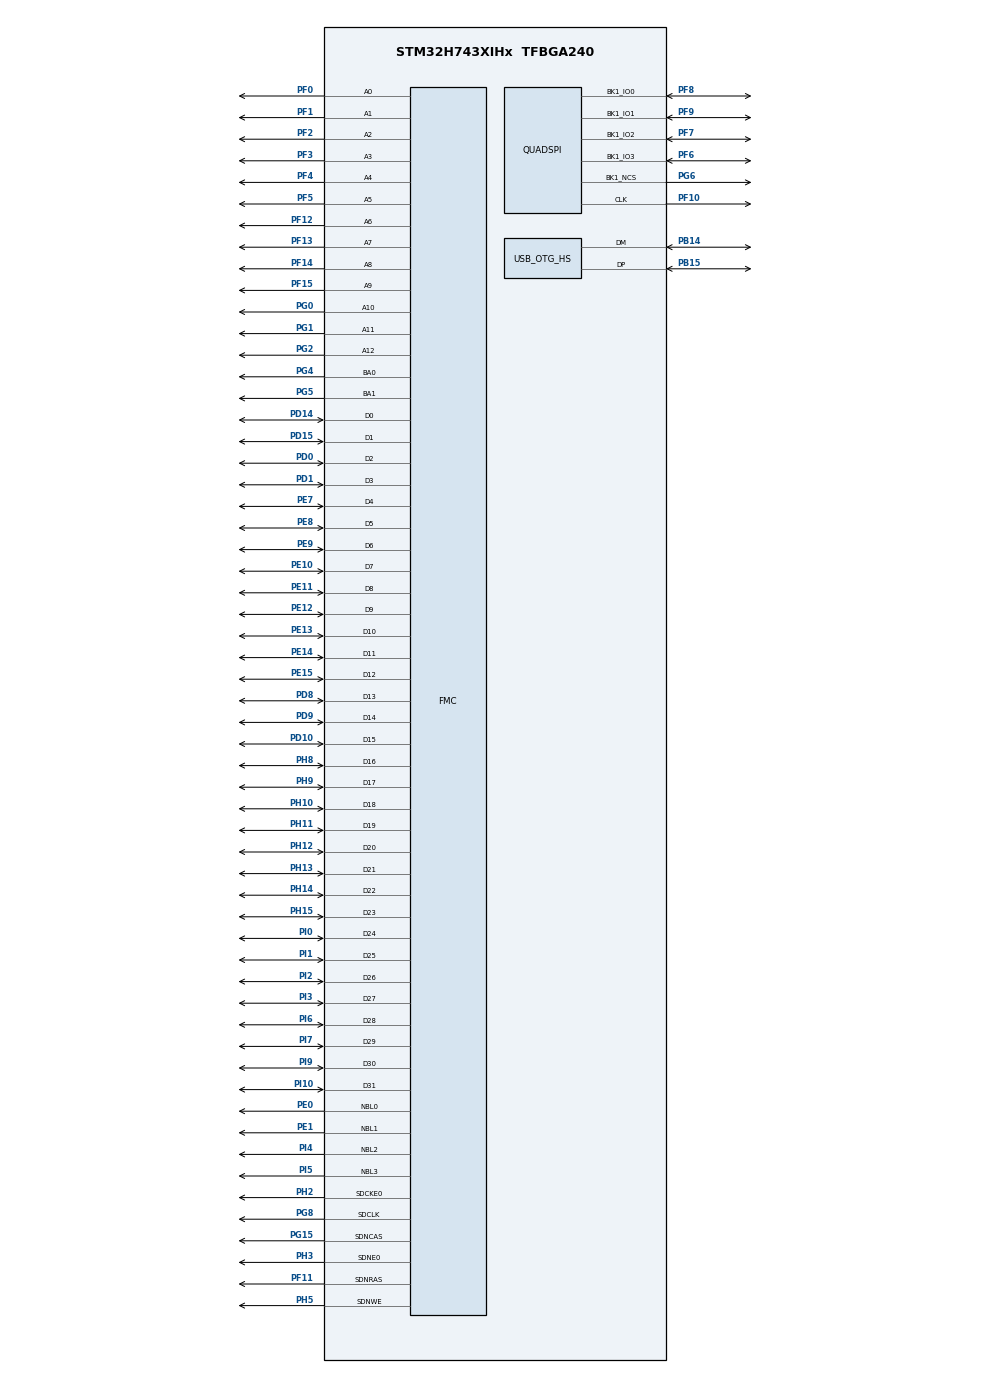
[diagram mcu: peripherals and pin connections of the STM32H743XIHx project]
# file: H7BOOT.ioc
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CORTEX_M7.AccessPermission_S-Cortex_Memory_Protection_Unit_Region1_Settings_S=MPU_REGION_FULL_ACCESS
CORTEX_M7.AccessPermission_S-Cortex_Memory_Protection_Unit_Region2_Settings_S=MPU_REGION_FULL_ACCESS
CORTEX_M7.AccessPermission_Spec=MPU_REGION_FULL_ACCESS
CORTEX_M7.BaseAddress_S-Cortex_Memory_Protection_Unit_Region1_Settings_S=0x90000000
CORTEX_M7.BaseAddress_S-Cortex_Memory_Protection_Unit_Region2_Settings_S=0xC0000000
CORTEX_M7.BaseAddress_Spec=0x24000000
CORTEX_M7.CPU_DCache=Enabled
CORTEX_M7.CPU_ICache=Enabled
CORTEX_M7.DisableExec_S-Cortex_Memory_Protection_Unit_Region2_Settings_S=MPU_INSTRUCTION_ACCESS_DISABLE
CORTEX_M7.Enable_S-Cortex_Memory_Protection_Unit_Region1_Settings_S=MPU_REGION_ENABLE
CORTEX_M7.Enable_S-Cortex_Memory_Protection_Unit_Region2_Settings_S=MPU_REGION_ENABLE
CORTEX_M7.Enable_Spec=MPU_REGION_ENABLE
CORTEX_M7.IsBufferable_S-Cortex_Memory_Protection_Unit_Region1_Settings_S=MPU_ACCESS_BUFFERABLE
CORTEX_M7.IsBufferable_S-Cortex_Memory_Protection_Unit_Region2_Settings_S=MPU_ACCESS_BUFFERABLE
CORTEX_M7.IsBufferable_Spec=MPU_ACCESS_BUFFERABLE
CORTEX_M7.IsCacheable_S-Cortex_Memory_Protection_Unit_Region1_Settings_S=MPU_ACCESS_CACHEABLE
CORTEX_M7.IsCacheable_S-Cortex_Memory_Protection_Unit_Region2_Settings_S=MPU_ACCESS_CACHEABLE
CORTEX_M7.IsCacheable_Spec=MPU_ACCESS_CACHEABLE
CORTEX_M7.IsShareable_S-Cortex_Memory_Protection_Unit_Region2_Settings_S=MPU_ACCESS_SHAREABLE
CORTEX_M7.MPU_Control=MPU_HFNMI_PRIVDEF
CORTEX_M7.Size_S-Cortex_Memory_Protection_Unit_Region1_Settings_S=MPU_REGION_SIZE_32MB
CORTEX_M7.Size_S-Cortex_Memory_Protection_Unit_Region2_Settings_S=MPU_REGION_SIZE_32MB
CORTEX_M7.Size_Spec=MPU_REGION_SIZE_128KB
CORTEX_M7.default_mode_Activation=1
FMC.CASLatency1=FMC_SDRAM_CAS_LATENCY_3
FMC.ColumnBitsNumber1=FMC_SDRAM_COLUMN_BITS_NUM_9
FMC.ExitSelfRefreshDelay1=14
FMC.LoadToActiveDelay1=2
FMC.RCDDelay1=4
FMC.RPDelay1=4
FMC.ReadBurst1=FMC_SDRAM_RBURST_ENABLE
FMC.ReadPipeDelay1=FMC_SDRAM_RPIPE_DELAY_1
FMC.RowCycleDelay1=13
FMC.SDClockPeriod1=FMC_SDRAM_CLOCK_PERIOD_2
FMC.SelfRefreshTime1=9
FMC.WriteRecoveryTime1=5
Mcu.Family=STM32H7
Mcu.Name=STM32H743XIHx
Mcu.Package=TFBGA240
NVIC.OTG_HS_IRQn=true\:0\:0\:false\:false\:true\:false\:true\:true
NVIC.PriorityGroup=NVIC_PRIORITYGROUP_4
PA13\ (JTMS/SWDIO).Mode=Serial_Wire
PA13\ (JTMS/SWDIO).Signal=DEBUG_JTMS-SWDIO
PA14\ (JTCK/SWCLK).Mode=Serial_Wire
PA14\ (JTCK/SWCLK).Signal=DEBUG_JTCK-SWCLK
PB14.GPIO_Speed=GPIO_SPEED_FREQ_VERY_HIGH
PB14.Mode=Host_FS
PB14.Signal=USB_OTG_HS_DM
PB15.GPIO_Speed=GPIO_SPEED_FREQ_VERY_HIGH
PB15.Mode=Host_FS
PB15.Signal=USB_OTG_HS_DP
PC14-OSC32_IN\ (OSC32_IN).Mode=LSE-External-Oscillator
PC14-OSC32_IN\ (OSC32_IN).Signal=RCC_OSC32_IN
PC15-OSC32_OUT\ (OSC32_OUT).Mode=LSE-External-Oscillator
PC15-OSC32_OUT\ (OSC32_OUT).Signal=RCC_OSC32_OUT
PD0.Signal=FMC_D2_DA2
PD1.Signal=FMC_D3_DA3
PD10.Signal=FMC_D15_DA15
PD14.Signal=FMC_D0_DA0
PD15.Signal=FMC_D1_DA1
PD8.Signal=FMC_D13_DA13
PD9.Signal=FMC_D14_DA14
PE0.Signal=FMC_NBL0
PE1.Signal=FMC_NBL1
PE10.Signal=FMC_D7_DA7
PE11.Signal=FMC_D8_DA8
PE12.Signal=FMC_D9_DA9
PE13.Signal=FMC_D10_DA10
PE14.Signal=FMC_D11_DA11
PE15.Signal=FMC_D12_DA12
PE7.Signal=FMC_D4_DA4
PE8.Signal=FMC_D5_DA5
PE9.Signal=FMC_D6_DA6
PF0.Signal=FMC_A0
PF1.Signal=FMC_A1
PF10.GPIO_Speed=GPIO_SPEED_FREQ_VERY_HIGH
PF10.Mode=Single Bank 1
PF10.Signal=QUADSPI_CLK
PF11.Signal=FMC_SDNRAS
PF12.Signal=FMC_A6
PF13.Signal=FMC_A7
PF14.Signal=FMC_A8
PF15.Signal=FMC_A9
PF2.Signal=FMC_A2
PF3.Signal=FMC_A3
PF4.Signal=FMC_A4
PF5.Signal=FMC_A5
PF6.GPIO_Speed=GPIO_SPEED_FREQ_VERY_HIGH
PF6.Mode=Single Bank 1
PF6.Signal=QUADSPI_BK1_IO3
PF7.GPIO_Speed=GPIO_SPEED_FREQ_VERY_HIGH
PF7.Mode=Single Bank 1
PF7.Signal=QUADSPI_BK1_IO2
PF8.GPIO_Speed=GPIO_SPEED_FREQ_VERY_HIGH
PF8.Mode=Single Bank 1
PF8.Signal=QUADSPI_BK1_IO0
PF9.GPIO_Speed=GPIO_SPEED_FREQ_VERY_HIGH
PF9.Mode=Single Bank 1
PF9.Signal=QUADSPI_BK1_IO1
PG0.Signal=FMC_A10
PG1.Signal=FMC_A11
PG15.Signal=FMC_SDNCAS
PG2.Signal=FMC_A12
PG4.Signal=FMC_A14_BA0
PG5.Signal=FMC_A15_BA1
PG6.GPIO_Speed=GPIO_SPEED_FREQ_VERY_HIGH
PG6.Mode=Single Bank 1
PG6.Signal=QUADSPI_BK1_NCS
PG8.Signal=FMC_SDCLK
PH0-OSC_IN\ (PH0).Mode=HSE-External-Oscillator
PH0-OSC_IN\ (PH0).Signal=RCC_OSC_IN
PH1-OSC_OUT\ (PH1).Mode=HSE-External-Oscillator
PH1-OSC_OUT\ (PH1).Signal=RCC_OSC_OUT
PH10.Signal=FMC_D18
PH11.Signal=FMC_D19
PH12.Signal=FMC_D20
PH13.Signal=FMC_D21
PH14.Signal=FMC_D22
PH15.Signal=FMC_D23
PH2.Mode=SdramChipSelect1_1
PH2.Signal=FMC_SDCKE0
PH3.Mode=SdramChipSelect1_1
PH3.Signal=FMC_SDNE0
PH5.Signal=FMC_SDNWE
PH8.Signal=FMC_D16
PH9.Signal=FMC_D17
PI0.Signal=FMC_D24
PI1.Signal=FMC_D25
PI10.Signal=FMC_D31
PI2.Signal=FMC_D26
PI3.Signal=FMC_D27
PI4.Signal=FMC_NBL2
PI5.Signal=FMC_NBL3
PI6.Signal=FMC_D28
PI7.Signal=FMC_D29
PI9.Signal=FMC_D30
ProjectManager.HeapSize=0x1000
ProjectManager.StackSize=0x2000
ProjectManager.TargetToolchain=CMake
QUADSPI.ChipSelectHighTime=QSPI_CS_HIGH_TIME_2_CYCLE
QUADSPI.ClockPrescaler=1
QUADSPI.FifoThreshold=4
QUADSPI.FlashSize=25
QUADSPI.SampleShifting=QSPI_SAMPLE_SHIFTING_HALFCYCLE
RCC.ADCFreq_Value=140000000
RCC.APB1Freq_Value=100000000
RCC.APB2Freq_Value=100000000
RCC.APB3Freq_Value=100000000
RCC.APB4Freq_Value=100000000
RCC.CortexFreq_Value=400000000
RCC.D1PPRE=RCC_APB3_DIV2
RCC.D2PPRE1=RCC_APB1_DIV2
RCC.D2PPRE2=RCC_APB2_DIV2
RCC.D3PPRE=RCC_APB4_DIV2
RCC.DIVM1=5
RCC.DIVM2=25
RCC.DIVM3=25
RCC.DIVN1=160
RCC.DIVN2=280
RCC.DIVN3=240
RCC.DIVQ1=16
RCC.HCLKFreq_Value=200000000
RCC.HPRE=RCC_HCLK_DIV2
RCC.PLL2FRACN=0
RCC.PLL3FRACN=0
RCC.PLLFRACN=0
RCC.PLLSourceVirtual=RCC_PLLSOURCE_HSE
RCC.SYSCLKFreq_VALUE=400000000
RCC.SYSCLKSource=RCC_SYSCLKSOURCE_PLLCLK
RCC.USBFreq_Value=50000000
SH.FMC_A0.0=FMC_A0,13b-sda1
SH.FMC_A1.0=FMC_A1,13b-sda1
SH.FMC_A10.0=FMC_A10,13b-sda1
SH.FMC_A11.0=FMC_A11,13b-sda1
SH.FMC_A12.0=FMC_A12,13b-sda1
SH.FMC_A14_BA0.0=FMC_BA0,FourSdramBanks1
SH.FMC_A15_BA1.0=FMC_BA1,FourSdramBanks1
SH.FMC_A2.0=FMC_A2,13b-sda1
SH.FMC_A3.0=FMC_A3,13b-sda1
SH.FMC_A4.0=FMC_A4,13b-sda1
SH.FMC_A5.0=FMC_A5,13b-sda1
SH.FMC_A6.0=FMC_A6,13b-sda1
SH.FMC_A7.0=FMC_A7,13b-sda1
SH.FMC_A8.0=FMC_A8,13b-sda1
SH.FMC_A9.0=FMC_A9,13b-sda1
SH.FMC_D0_DA0.0=FMC_D0,sd-32b-d1
SH.FMC_D10_DA10.0=FMC_D10,sd-32b-d1
SH.FMC_D11_DA11.0=FMC_D11,sd-32b-d1
SH.FMC_D12_DA12.0=FMC_D12,sd-32b-d1
SH.FMC_D13_DA13.0=FMC_D13,sd-32b-d1
SH.FMC_D14_DA14.0=FMC_D14,sd-32b-d1
SH.FMC_D15_DA15.0=FMC_D15,sd-32b-d1
SH.FMC_D16.0=FMC_D16,sd-32b-d1
SH.FMC_D17.0=FMC_D17,sd-32b-d1
SH.FMC_D18.0=FMC_D18,sd-32b-d1
SH.FMC_D19.0=FMC_D19,sd-32b-d1
SH.FMC_D1_DA1.0=FMC_D1,sd-32b-d1
SH.FMC_D20.0=FMC_D20,sd-32b-d1
SH.FMC_D21.0=FMC_D21,sd-32b-d1
SH.FMC_D22.0=FMC_D22,sd-32b-d1
SH.FMC_D23.0=FMC_D23,sd-32b-d1
SH.FMC_D24.0=FMC_D24,sd-32b-d1
SH.FMC_D25.0=FMC_D25,sd-32b-d1
SH.FMC_D26.0=FMC_D26,sd-32b-d1
SH.FMC_D27.0=FMC_D27,sd-32b-d1
SH.FMC_D28.0=FMC_D28,sd-32b-d1
SH.FMC_D29.0=FMC_D29,sd-32b-d1
SH.FMC_D2_DA2.0=FMC_D2,sd-32b-d1
SH.FMC_D30.0=FMC_D30,sd-32b-d1
SH.FMC_D31.0=FMC_D31,sd-32b-d1
SH.FMC_D3_DA3.0=FMC_D3,sd-32b-d1
SH.FMC_D4_DA4.0=FMC_D4,sd-32b-d1
SH.FMC_D5_DA5.0=FMC_D5,sd-32b-d1
SH.FMC_D6_DA6.0=FMC_D6,sd-32b-d1
SH.FMC_D7_DA7.0=FMC_D7,sd-32b-d1
SH.FMC_D8_DA8.0=FMC_D8,sd-32b-d1
SH.FMC_D9_DA9.0=FMC_D9,sd-32b-d1
SH.FMC_NBL0.0=FMC_NBL0,Sd4ByteEnable1
SH.FMC_NBL1.0=FMC_NBL1,Sd4ByteEnable1
SH.FMC_NBL2.0=FMC_NBL2,Sd4ByteEnable1
SH.FMC_NBL3.0=FMC_NBL3,Sd4ByteEnable1
SH.FMC_SDCLK.0=FMC_SDCLK,13b-sda1
SH.FMC_SDNCAS.0=FMC_SDNCAS,13b-sda1
SH.FMC_SDNRAS.0=FMC_SDNRAS,13b-sda1
SH.FMC_SDNWE.0=FMC_SDNWE,13b-sda1
USB_HOST.SW_VBUS_DRIVE_MSC_HS=true
USB_HOST.USBH_HandleTypeDef-MSC_HS=hUsbHostHS
USB_HOST.VirtualModeHS=Msc
USB_OTG_HS.VirtualMode-Host_FS=Host_FS
VP_CRC_VS_CRC.Mode=CRC_Activate
VP_FATFS_VS_USB.Mode=USB
VP_IWDG1_VS_IWDG.Mode=IWDG_Activate
VP_MEMORYMAP_VS_MEMORYMAP.Mode=CurAppReg
VP_USB_HOST_VS_USB_HOST_MSC_HS.Mode=MSC_HS
board=custom

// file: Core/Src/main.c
/* USER CODE BEGIN Header */
/**
  ******************************************************************************
  * @file           : main.c
  * @brief          : Main program body
  ******************************************************************************
  * @attention
  *
  * Copyright (c) 2025 STMicroelectronics.
  * All rights reserved.
  *
  * This software is licensed under terms that can be found in the LICENSE file
  * in the root directory of this software component.
  * If no LICENSE file comes with this software, it is provided AS-IS.
  *
  ******************************************************************************
  */
/* USER CODE END Header */
#include "main.h"
#include "fatfs.h"
#include "usb_host.h"

/* USER CODE BEGIN Includes */
#include "app.h"
// #include "bsp.h"
/* USER CODE END Includes */

CRC_HandleTypeDef hcrc;

IWDG_HandleTypeDef hiwdg1;

QSPI_HandleTypeDef hqspi;

SDRAM_HandleTypeDef hsdram1;

void SystemClock_Config(void);
static void MPU_Config(void);
static void MX_GPIO_Init(void);
static void MX_FMC_Init(void);
static void MX_QUADSPI_Init(void);
static void MX_IWDG1_Init(void);
static void MX_CRC_Init(void);
void MX_USB_HOST_Process(void);

int main(void)
{

  /* MPU Configuration--------------------------------------------------------*/
  MPU_Config();

  /* Enable the CPU Cache */

  /* Enable I-Cache---------------------------------------------------------*/
  SCB_EnableICache();

  /* Enable D-Cache---------------------------------------------------------*/
  SCB_EnableDCache();

  /* MCU Configuration--------------------------------------------------------*/

  /* Reset of all peripherals, Initializes the Flash interface and the Systick. */
  HAL_Init();

  /* Configure the system clock */
  SystemClock_Config();

  /* Initialize all configured peripherals */
  MX_GPIO_Init();
  MX_FMC_Init();
  MX_QUADSPI_Init();
  MX_FATFS_Init();
  MX_USB_HOST_Init();
  MX_IWDG1_Init();
  MX_CRC_Init();

  /* Infinite loop */
  /* USER CODE BEGIN WHILE */
  while (1)
  {
    HAL_IWDG_Refresh(&hiwdg1);
    /* USER CODE END WHILE */
    MX_USB_HOST_Process();

  }
}

void SystemClock_Config(void)
{
  RCC_OscInitTypeDef RCC_OscInitStruct = {0};
  RCC_ClkInitTypeDef RCC_ClkInitStruct = {0};

  /** Supply configuration update enable
  */
  HAL_PWREx_ConfigSupply(PWR_LDO_SUPPLY);

  /** Configure the main internal regulator output voltage
  */
  __HAL_PWR_VOLTAGESCALING_CONFIG(PWR_REGULATOR_VOLTAGE_SCALE1);

  while(!__HAL_PWR_GET_FLAG(PWR_FLAG_VOSRDY)) {}

  /** Initializes the RCC Oscillators according to the specified parameters
  * in the RCC_OscInitTypeDef structure.
  */
  RCC_OscInitStruct.OscillatorType = RCC_OSCILLATORTYPE_LSI|RCC_OSCILLATORTYPE_HSE;
  RCC_OscInitStruct.HSEState = RCC_HSE_ON;
  RCC_OscInitStruct.LSIState = RCC_LSI_ON;
  RCC_OscInitStruct.PLL.PLLState = RCC_PLL_ON;
  RCC_OscInitStruct.PLL.PLLSource = RCC_PLLSOURCE_HSE;
  RCC_OscInitStruct.PLL.PLLM = 5;
  RCC_OscInitStruct.PLL.PLLN = 160;
  RCC_OscInitStruct.PLL.PLLP = 2;
  RCC_OscInitStruct.PLL.PLLQ = 16;
  RCC_OscInitStruct.PLL.PLLR = 2;
  RCC_OscInitStruct.PLL.PLLRGE = RCC_PLL1VCIRANGE_2;
  RCC_OscInitStruct.PLL.PLLVCOSEL = RCC_PLL1VCOWIDE;
  RCC_OscInitStruct.PLL.PLLFRACN = 0;
  if (HAL_RCC_OscConfig(&RCC_OscInitStruct) != HAL_OK)
  {
    Error_Handler();
  }

  /** Initializes the CPU, AHB and APB buses clocks
  */
  RCC_ClkInitStruct.ClockType = RCC_CLOCKTYPE_HCLK|RCC_CLOCKTYPE_SYSCLK
                              |RCC_CLOCKTYPE_PCLK1|RCC_CLOCKTYPE_PCLK2
                              |RCC_CLOCKTYPE_D3PCLK1|RCC_CLOCKTYPE_D1PCLK1;
  RCC_ClkInitStruct.SYSCLKSource = RCC_SYSCLKSOURCE_PLLCLK;
  RCC_ClkInitStruct.SYSCLKDivider = RCC_SYSCLK_DIV1;
  RCC_ClkInitStruct.AHBCLKDivider = RCC_HCLK_DIV2;
  RCC_ClkInitStruct.APB3CLKDivider = RCC_APB3_DIV2;
  RCC_ClkInitStruct.APB1CLKDivider = RCC_APB1_DIV2;
  RCC_ClkInitStruct.APB2CLKDivider = RCC_APB2_DIV2;
  RCC_ClkInitStruct.APB4CLKDivider = RCC_APB4_DIV2;

  if (HAL_RCC_ClockConfig(&RCC_ClkInitStruct, FLASH_LATENCY_2) != HAL_OK)
  {
    Error_Handler();
  }
}

static void MX_CRC_Init(void)
{

  hcrc.Instance = CRC;
  hcrc.Init.DefaultPolynomialUse = DEFAULT_POLYNOMIAL_ENABLE;
  hcrc.Init.DefaultInitValueUse = DEFAULT_INIT_VALUE_ENABLE;
  hcrc.Init.InputDataInversionMode = CRC_INPUTDATA_INVERSION_NONE;
  hcrc.Init.OutputDataInversionMode = CRC_OUTPUTDATA_INVERSION_DISABLE;
  hcrc.InputDataFormat = CRC_INPUTDATA_FORMAT_BYTES;
  if (HAL_CRC_Init(&hcrc) != HAL_OK)
  {
    Error_Handler();
  }

}

static void MX_IWDG1_Init(void)
{

  hiwdg1.Instance = IWDG1;
  hiwdg1.Init.Prescaler = IWDG_PRESCALER_4;
  hiwdg1.Init.Window = 4095;
  hiwdg1.Init.Reload = 4095;
  if (HAL_IWDG_Init(&hiwdg1) != HAL_OK)
  {
    Error_Handler();
  }

}

static void MX_QUADSPI_Init(void)
{

  /* QUADSPI parameter configuration*/
  hqspi.Instance = QUADSPI;
  hqspi.Init.ClockPrescaler = 1;
  hqspi.Init.FifoThreshold = 4;
  hqspi.Init.SampleShifting = QSPI_SAMPLE_SHIFTING_HALFCYCLE;
  hqspi.Init.FlashSize = 25;
  hqspi.Init.ChipSelectHighTime = QSPI_CS_HIGH_TIME_2_CYCLE;
  hqspi.Init.ClockMode = QSPI_CLOCK_MODE_0;
  hqspi.Init.FlashID = QSPI_FLASH_ID_1;
  hqspi.Init.DualFlash = QSPI_DUALFLASH_DISABLE;
  if (HAL_QSPI_Init(&hqspi) != HAL_OK)
  {
    Error_Handler();
  }

}

/* FMC initialization function */
static void MX_FMC_Init(void)
{

  FMC_SDRAM_TimingTypeDef SdramTiming = {0};

  /** Perform the SDRAM1 memory initialization sequence
  */
  hsdram1.Instance = FMC_SDRAM_DEVICE;
  /* hsdram1.Init */
  hsdram1.Init.SDBank = FMC_SDRAM_BANK1;
  hsdram1.Init.ColumnBitsNumber = FMC_SDRAM_COLUMN_BITS_NUM_9;
  hsdram1.Init.RowBitsNumber = FMC_SDRAM_ROW_BITS_NUM_13;
  hsdram1.Init.MemoryDataWidth = FMC_SDRAM_MEM_BUS_WIDTH_32;
  hsdram1.Init.InternalBankNumber = FMC_SDRAM_INTERN_BANKS_NUM_4;
  hsdram1.Init.CASLatency = FMC_SDRAM_CAS_LATENCY_3;
  hsdram1.Init.WriteProtection = FMC_SDRAM_WRITE_PROTECTION_DISABLE;
  hsdram1.Init.SDClockPeriod = FMC_SDRAM_CLOCK_PERIOD_2;
  hsdram1.Init.ReadBurst = FMC_SDRAM_RBURST_ENABLE;
  hsdram1.Init.ReadPipeDelay = FMC_SDRAM_RPIPE_DELAY_1;
  /* SdramTiming */
  SdramTiming.LoadToActiveDelay = 2;
  SdramTiming.ExitSelfRefreshDelay = 14;
  SdramTiming.SelfRefreshTime = 9;
  SdramTiming.RowCycleDelay = 13;
  SdramTiming.WriteRecoveryTime = 5;
  SdramTiming.RPDelay = 4;
  SdramTiming.RCDDelay = 4;

  if (HAL_SDRAM_Init(&hsdram1, &SdramTiming) != HAL_OK)
  {
    Error_Handler( );
  }

}

static void MX_GPIO_Init(void)
{

  /* GPIO Ports Clock Enable */
  __HAL_RCC_GPIOI_CLK_ENABLE();
  __HAL_RCC_GPIOE_CLK_ENABLE();
  __HAL_RCC_GPIOA_CLK_ENABLE();
  __HAL_RCC_GPIOH_CLK_ENABLE();
  __HAL_RCC_GPIOC_CLK_ENABLE();
  __HAL_RCC_GPIOG_CLK_ENABLE();
  __HAL_RCC_GPIOD_CLK_ENABLE();
  __HAL_RCC_GPIOF_CLK_ENABLE();
  __HAL_RCC_GPIOB_CLK_ENABLE();

}

 /* MPU Configuration */

void MPU_Config(void)
{
  MPU_Region_InitTypeDef MPU_InitStruct = {0};

  /* Disables the MPU */
  HAL_MPU_Disable();

  /** Initializes and configures the Region and the memory to be protected
  */
  MPU_InitStruct.Enable = MPU_REGION_ENABLE;
  MPU_InitStruct.Number = MPU_REGION_NUMBER0;
  MPU_InitStruct.BaseAddress = 0x24000000;
  MPU_InitStruct.Size = MPU_REGION_SIZE_128KB;
  MPU_InitStruct.SubRegionDisable = 0x87;
  MPU_InitStruct.TypeExtField = MPU_TEX_LEVEL0;
  MPU_InitStruct.AccessPermission = MPU_REGION_FULL_ACCESS;
  MPU_InitStruct.DisableExec = MPU_INSTRUCTION_ACCESS_DISABLE;
  MPU_InitStruct.IsShareable = MPU_ACCESS_SHAREABLE;
  MPU_InitStruct.IsCacheable = MPU_ACCESS_CACHEABLE;
  MPU_InitStruct.IsBufferable = MPU_ACCESS_BUFFERABLE;

  HAL_MPU_ConfigRegion(&MPU_InitStruct);

  /** Initializes and configures the Region and the memory to be protected
  */
  MPU_InitStruct.Number = MPU_REGION_NUMBER1;
  MPU_InitStruct.BaseAddress = 0x90000000;
  MPU_InitStruct.Size = MPU_REGION_SIZE_32MB;
  MPU_InitStruct.SubRegionDisable = 0x0;
  MPU_InitStruct.DisableExec = MPU_INSTRUCTION_ACCESS_ENABLE;
  MPU_InitStruct.IsShareable = MPU_ACCESS_NOT_SHAREABLE;

  HAL_MPU_ConfigRegion(&MPU_InitStruct);

  /** Initializes and configures the Region and the memory to be protected
  */
  MPU_InitStruct.Number = MPU_REGION_NUMBER2;
  MPU_InitStruct.BaseAddress = 0xC0000000;
  MPU_InitStruct.DisableExec = MPU_INSTRUCTION_ACCESS_DISABLE;
  MPU_InitStruct.IsShareable = MPU_ACCESS_SHAREABLE;

  HAL_MPU_ConfigRegion(&MPU_InitStruct);
  /* Enables the MPU */
  HAL_MPU_Enable(MPU_HFNMI_PRIVDEF);

}

void Error_Handler(void)
{
  __disable_irq();
  while (1)
  {
  }
}
